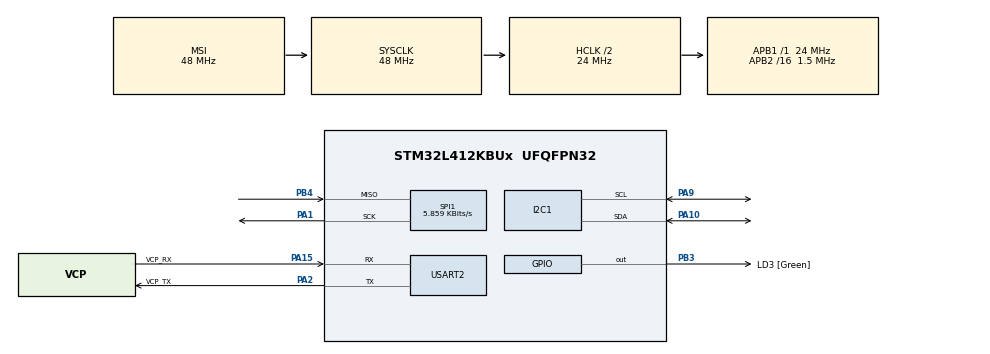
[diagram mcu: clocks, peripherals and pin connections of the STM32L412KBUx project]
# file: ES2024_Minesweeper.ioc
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I2C1.Timing=0x00506682
Mcu.Family=STM32L4
Mcu.Name=STM32L412KBUx
Mcu.Package=UFQFPN32
NVIC.PriorityGroup=NVIC_PRIORITYGROUP_4
PA0-CK_IN.Mode=HSE-External-Clock-Source-for-LittleOrca
PA0-CK_IN.Signal=RCC_CK_IN
PA1.Mode=RX_Only_Simplex_Unidirect_Master
PA1.Signal=SPI1_SCK
PA10.Mode=I2C
PA10.Signal=I2C1_SDA
PA13\ (JTMS/SWDIO).GPIO_Label=SWDIO
PA13\ (JTMS/SWDIO).Mode=Serial_Wire
PA13\ (JTMS/SWDIO).Signal=SYS_JTMS-SWDIO
PA14\ (JTCK/SWCLK).GPIO_Label=SWCLK
PA14\ (JTCK/SWCLK).Mode=Serial_Wire
PA14\ (JTCK/SWCLK).Signal=SYS_JTCK-SWCLK
PA15\ (JTDI).GPIO_Label=VCP_RX
PA15\ (JTDI).Mode=Asynchronous
PA15\ (JTDI).Signal=USART2_RX
PA2.GPIO_Label=VCP_TX
PA2.Mode=Asynchronous
PA2.Signal=USART2_TX
PA9.Mode=I2C
PA9.Signal=I2C1_SCL
PB3\ (JTDO/TRACESWO).GPIO_Label=LD3 [Green]
PB3\ (JTDO/TRACESWO).Signal=GPIO_Output
PB4\ (NJTRST).Mode=RX_Only_Simplex_Unidirect_Master
PB4\ (NJTRST).Signal=SPI1_MISO
PC14-OSC32_IN\ (PC14).Mode=LSE-External-Oscillator
PC14-OSC32_IN\ (PC14).Signal=RCC_OSC32_IN
PC15-OSC32_OUT\ (PC15).Mode=LSE-External-Oscillator
PC15-OSC32_OUT\ (PC15).Signal=RCC_OSC32_OUT
ProjectManager.HeapSize=0x200
ProjectManager.StackSize=0x400
ProjectManager.TargetToolchain=STM32CubeIDE
RCC.ADCFreq_Value=48000000
RCC.AHBCLKDivider=RCC_SYSCLK_DIV2
RCC.AHBFreq_Value=24000000
RCC.APB1Freq_Value=24000000
RCC.APB1TimFreq_Value=24000000
RCC.APB2CLKDivider=RCC_HCLK_DIV16
RCC.APB2Freq_Value=1500000
RCC.APB2TimFreq_Value=3000000
RCC.CortexFreq_Value=24000000
RCC.FLatency=FLASH_LATENCY_1
RCC.HCLKFreq_Value=24000000
RCC.HSE_VALUE=8000000
RCC.HSI48_VALUE=48000000
RCC.HSICalibrationValue=64
RCC.HSI_VALUE=16000000
RCC.LSE_Drive_Capability=RCC_LSEDRIVE_LOW
RCC.MSIClockRange=RCC_MSIRANGE_11
RCC.MSI_VALUE=48000000
RCC.SYSCLKFreq_VALUE=48000000
RCC.USBFreq_Value=48000000
RCC.VCOOutputFreq_Value=384000000
SPI1.BaudRatePrescaler=SPI_BAUDRATEPRESCALER_256
SPI1.CLKPhase=SPI_PHASE_2EDGE
SPI1.CLKPolarity=SPI_POLARITY_HIGH
SPI1.CalculateBaudRate=5.859 KBits/s
SPI1.DataSize=SPI_DATASIZE_16BIT
SPI1.Direction=SPI_DIRECTION_2LINES_RXONLY
SPI1.FirstBit=SPI_FIRSTBIT_LSB
SPI1.Mode=SPI_MODE_MASTER
SPI1.VirtualType=VM_MASTER
USART2.VirtualMode-Asynchronous=VM_ASYNC
board=NUCLEO-L412KB

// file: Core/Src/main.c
/* USER CODE BEGIN Header */
/**
  ******************************************************************************
  * @file           : main.c
  * @brief          : Main program body
  ******************************************************************************
  * @attention
  *
  * Copyright (c) 2024 STMicroelectronics.
  * All rights reserved.
  *
  * This software is licensed under terms that can be found in the LICENSE file
  * in the root directory of this software component.
  * If no LICENSE file comes with this software, it is provided AS-IS.
  *
  ******************************************************************************
  */
/* USER CODE END Header */
#include "main.h"
#include "i2c.h"
#include "spi.h"
#include "usart.h"
#include "gpio.h"

/* USER CODE BEGIN Includes */
#include "keyboard.h"
#include "minesweeper.h"
#include <stdio.h>
#include "retarget_stdio.h"
/* USER CODE END Includes */

void SystemClock_Config(void);

int main(void)
{

  /* MCU Configuration--------------------------------------------------------*/

  /* Reset of all peripherals, Initializes the Flash interface and the Systick. */
  HAL_Init();

  /* Configure the system clock */
  SystemClock_Config();

  /* Initialize all configured peripherals */
  MX_GPIO_Init();
  MX_USART2_UART_Init();
  MX_SPI1_Init();
  MX_I2C1_Init();
  /* USER CODE BEGIN 2 */
  keyboard_init(&hspi1, 10);
  RetargetInit(&huart2);
  /* USER CODE END 2 */

  /* Infinite loop */
  /* USER CODE BEGIN WHILE */
  char buffer[100];
  while (1)
  {
	  printf(buffer, 100, "Test123");
	  playGame();
	  /*if(0 != is_key()) // nur zum Debuggen, test der keyboard lib
	  {
		  HAL_GPIO_TogglePin(LD3_GPIO_Port, LD3_Pin);
	  }*/
    /* USER CODE END WHILE */

  }
}

void SystemClock_Config(void)
{
  RCC_OscInitTypeDef RCC_OscInitStruct = {0};
  RCC_ClkInitTypeDef RCC_ClkInitStruct = {0};

  /** Configure the main internal regulator output voltage
  */
  if (HAL_PWREx_ControlVoltageScaling(PWR_REGULATOR_VOLTAGE_SCALE1) != HAL_OK)
  {
    Error_Handler();
  }

  /** Configure LSE Drive Capability
  */
  HAL_PWR_EnableBkUpAccess();
  __HAL_RCC_LSEDRIVE_CONFIG(RCC_LSEDRIVE_LOW);

  /** Initializes the RCC Oscillators according to the specified parameters
  * in the RCC_OscInitTypeDef structure.
  */
  RCC_OscInitStruct.OscillatorType = RCC_OSCILLATORTYPE_LSE|RCC_OSCILLATORTYPE_MSI;
  RCC_OscInitStruct.LSEState = RCC_LSE_ON;
  RCC_OscInitStruct.MSIState = RCC_MSI_ON;
  RCC_OscInitStruct.MSICalibrationValue = 0;
  RCC_OscInitStruct.MSIClockRange = RCC_MSIRANGE_11;
  RCC_OscInitStruct.PLL.PLLState = RCC_PLL_NONE;
  if (HAL_RCC_OscConfig(&RCC_OscInitStruct) != HAL_OK)
  {
    Error_Handler();
  }

  /** Initializes the CPU, AHB and APB buses clocks
  */
  RCC_ClkInitStruct.ClockType = RCC_CLOCKTYPE_HCLK|RCC_CLOCKTYPE_SYSCLK
                              |RCC_CLOCKTYPE_PCLK1|RCC_CLOCKTYPE_PCLK2;
  RCC_ClkInitStruct.SYSCLKSource = RCC_SYSCLKSOURCE_MSI;
  RCC_ClkInitStruct.AHBCLKDivider = RCC_SYSCLK_DIV2;
  RCC_ClkInitStruct.APB1CLKDivider = RCC_HCLK_DIV1;
  RCC_ClkInitStruct.APB2CLKDivider = RCC_HCLK_DIV16;

  if (HAL_RCC_ClockConfig(&RCC_ClkInitStruct, FLASH_LATENCY_1) != HAL_OK)
  {
    Error_Handler();
  }

  /** Enable MSI Auto calibration
  */
  HAL_RCCEx_EnableMSIPLLMode();
}

void Error_Handler(void)
{
  __disable_irq();
  while (1)
  {
  }
}
